# VTM_ECC_AGGR_00B02000h register map
Vendor: Texas Instruments
Peripheral module from a debugger description file (folder AM275x).
Registers are 32-bit, access not given, reset 0x0 unless marked. A register's access mark holds for its fields unless they carry their own. Offsets are as the file gives them; lines under a group give offsets from that group; [hi:lo] are bit positions; {n}, {i} and the like mark numbered series; 'fields as' and 'values as' point back to an identical list; <NAME> marks a mode.

## ecc_aggr
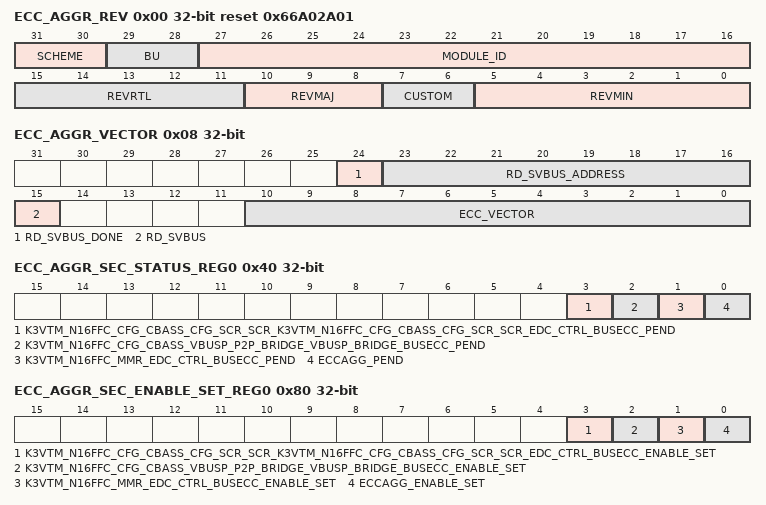
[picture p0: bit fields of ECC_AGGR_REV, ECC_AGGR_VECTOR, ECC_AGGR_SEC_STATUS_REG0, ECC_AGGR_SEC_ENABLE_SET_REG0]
0x00 ECC_AGGR_REV ro reset 0x66A02A01 — Revision parameters
  [31:30] SCHEME
  [29:28] BU — Business Unit
  [27:16] MODULE_ID
  [15:11] REVRTL — RTL version
  [10:8] REVMAJ — Major version
  [7:6] CUSTOM — Custom version
  [5:0] REVMIN — Minor version
0x08 ECC_AGGR_VECTOR — ECC Vector Register
  [24] RD_SVBUS_DONE — Status to indicate if read on serial VBUS is complete, write of any value will clear this bit. (access R/W1TC)
  [23:16] RD_SVBUS_ADDRESS rw — Read address
  [15] RD_SVBUS — Write 1 to trigger a read on the serial VBUS (access R/W1TS)
  [10:0] ECC_VECTOR rw — Value written to select the corresponding ECC RAM for control or status
0x0C ECC_AGGR_STAT ro reset 0x4 — Misc Status
  [10:0] NUM_RAMS — Indicates the number of RAMS serviced by the ECC aggregator
0x10 ECC_AGGR_RESERVED_SVBUS_j rw — Reference other documents that contain the ECC RAM wrapper and EDC controller serial vbus register sets.
  [31:0] DATA — Serial VBUS register data
0x3C ECC_AGGR_SEC_EOI_REG — EOI Register
  [0] EOI_WR — EOI Register (access R/W1TS)
0x40 ECC_AGGR_SEC_STATUS_REG0 — Interrupt Status Register 0
  [3] K3VTM_N16FFC_CFG_CBASS_CFG_SCR_SCR_K3VTM_N16FFC_CFG_CBASS_CFG_SCR_SCR_EDC_CTRL_BUSECC_PEND — Interrupt Pending Status for k3vtm_n16ffc_cfg_cbass_cfg_scr_scr_k3vtm_n16ffc_cfg_cbass_cfg_scr_scr_edc_ctrl_busecc_pend (access R/W1TS)
  [2] K3VTM_N16FFC_CFG_CBASS_VBUSP_P2P_BRIDGE_VBUSP_BRIDGE_BUSECC_PEND — Interrupt Pending Status for k3vtm_n16ffc_cfg_cbass_vbusp_p2p_bridge_vbusp_bridge_busecc_pend (access R/W1TS)
  [1] K3VTM_N16FFC_MMR_EDC_CTRL_BUSECC_PEND — Interrupt Pending Status for k3vtm_n16ffc_mmr_edc_ctrl_busecc_pend (access R/W1TS)
  [0] ECCAGG_PEND — Interrupt Pending Status for eccagg_pend (access R/W1TS)
0x80 ECC_AGGR_SEC_ENABLE_SET_REG0 — Interrupt Enable Set Register 0
  [3] K3VTM_N16FFC_CFG_CBASS_CFG_SCR_SCR_K3VTM_N16FFC_CFG_CBASS_CFG_SCR_SCR_EDC_CTRL_BUSECC_ENABLE_SET — Interrupt Enable Set Register for k3vtm_n16ffc_cfg_cbass_cfg_scr_scr_k3vtm_n16ffc_cfg_cbass_cfg_scr_scr_edc_ctrl_busecc_pend (access R/W1TS)
  [2] K3VTM_N16FFC_CFG_CBASS_VBUSP_P2P_BRIDGE_VBUSP_BRIDGE_BUSECC_ENABLE_SET — Interrupt Enable Set Register for k3vtm_n16ffc_cfg_cbass_vbusp_p2p_bridge_vbusp_bridge_busecc_pend (access R/W1TS)
  [1] K3VTM_N16FFC_MMR_EDC_CTRL_BUSECC_ENABLE_SET — Interrupt Enable Set Register for k3vtm_n16ffc_mmr_edc_ctrl_busecc_pend (access R/W1TS)
  [0] ECCAGG_ENABLE_SET — Interrupt Enable Set Register for eccagg_pend (access R/W1TS)
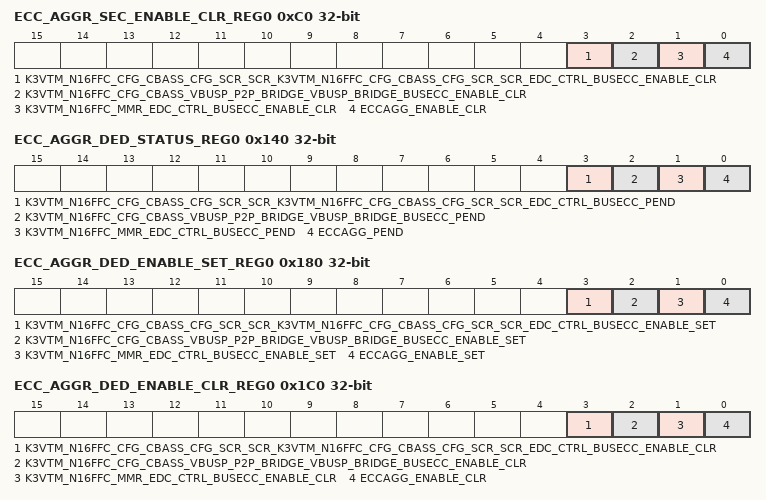
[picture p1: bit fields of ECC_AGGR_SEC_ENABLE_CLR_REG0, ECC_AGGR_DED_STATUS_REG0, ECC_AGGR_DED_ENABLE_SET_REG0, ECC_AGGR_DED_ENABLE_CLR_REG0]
0xC0 ECC_AGGR_SEC_ENABLE_CLR_REG0 — Interrupt Enable Clear Register 0
  [3] K3VTM_N16FFC_CFG_CBASS_CFG_SCR_SCR_K3VTM_N16FFC_CFG_CBASS_CFG_SCR_SCR_EDC_CTRL_BUSECC_ENABLE_CLR — Interrupt Enable Clear Register for k3vtm_n16ffc_cfg_cbass_cfg_scr_scr_k3vtm_n16ffc_cfg_cbass_cfg_scr_scr_edc_ctrl_busecc_pend (access R/W1TC)
  [2] K3VTM_N16FFC_CFG_CBASS_VBUSP_P2P_BRIDGE_VBUSP_BRIDGE_BUSECC_ENABLE_CLR — Interrupt Enable Clear Register for k3vtm_n16ffc_cfg_cbass_vbusp_p2p_bridge_vbusp_bridge_busecc_pend (access R/W1TC)
  [1] K3VTM_N16FFC_MMR_EDC_CTRL_BUSECC_ENABLE_CLR — Interrupt Enable Clear Register for k3vtm_n16ffc_mmr_edc_ctrl_busecc_pend (access R/W1TC)
  [0] ECCAGG_ENABLE_CLR — Interrupt Enable Clear Register for eccagg_pend (access R/W1TC)
0x13C ECC_AGGR_DED_EOI_REG — EOI Register
  [0] EOI_WR — EOI Register (access R/W1TS)
0x140 ECC_AGGR_DED_STATUS_REG0 — Interrupt Status Register 0
  fields as ECC_AGGR_SEC_STATUS_REG0
0x180 ECC_AGGR_DED_ENABLE_SET_REG0 — Interrupt Enable Set Register 0
  fields as ECC_AGGR_SEC_ENABLE_SET_REG0
0x1C0 ECC_AGGR_DED_ENABLE_CLR_REG0 — Interrupt Enable Clear Register 0
  fields as ECC_AGGR_SEC_ENABLE_CLR_REG0
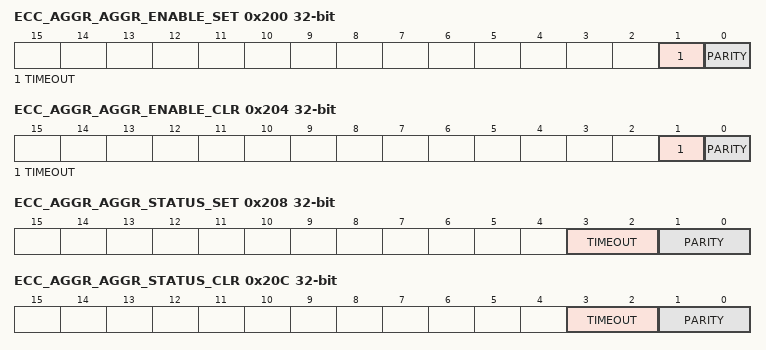
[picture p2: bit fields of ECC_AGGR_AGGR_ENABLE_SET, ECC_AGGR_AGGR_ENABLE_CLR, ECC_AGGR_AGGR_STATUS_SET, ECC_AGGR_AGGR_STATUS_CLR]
0x200 ECC_AGGR_AGGR_ENABLE_SET — AGGR interrupt enable set Register
  [1] TIMEOUT — interrupt enable set for svbus timeout errors (access R/W1TS)
  [0] PARITY — interrupt enable set for parity errors (access R/W1TS)
0x204 ECC_AGGR_AGGR_ENABLE_CLR — AGGR interrupt enable clear Register
  [1] TIMEOUT — interrupt enable clear for svbus timeout errors (access R/W1TC)
  [0] PARITY — interrupt enable clear for parity errors (access R/W1TC)
0x208 ECC_AGGR_AGGR_STATUS_SET — AGGR interrupt status set Register
  [3:2] TIMEOUT — interrupt status set for svbus timeout errors (access R/WI)
  [1:0] PARITY — interrupt status set for parity errors (access R/WI)
0x20C ECC_AGGR_AGGR_STATUS_CLR — AGGR interrupt status clear Register
  [3:2] TIMEOUT — interrupt status clear for svbus timeout errors (access R/WD)
  [1:0] PARITY — interrupt status clear for parity errors (access R/WD)
